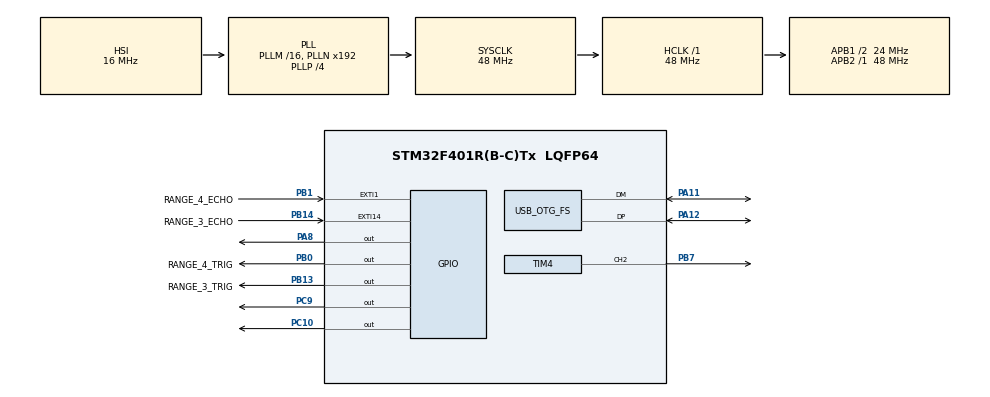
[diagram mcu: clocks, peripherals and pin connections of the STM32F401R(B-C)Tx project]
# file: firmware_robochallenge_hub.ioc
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Dma.Request0=TIM4_CH2
Dma.TIM4_CH2.0.Direction=DMA_MEMORY_TO_PERIPH
Dma.TIM4_CH2.0.FIFOMode=DMA_FIFOMODE_DISABLE
Dma.TIM4_CH2.0.Instance=DMA1_Stream3
Dma.TIM4_CH2.0.MemDataAlignment=DMA_MDATAALIGN_HALFWORD
Dma.TIM4_CH2.0.MemInc=DMA_MINC_ENABLE
Dma.TIM4_CH2.0.Mode=DMA_NORMAL
Dma.TIM4_CH2.0.PeriphDataAlignment=DMA_PDATAALIGN_HALFWORD
Dma.TIM4_CH2.0.PeriphInc=DMA_PINC_DISABLE
Dma.TIM4_CH2.0.Priority=DMA_PRIORITY_VERY_HIGH
FREERTOS.Tasks01=test_task,24,128,test_task_fun,Default,NULL,Dynamic,NULL,NULL;DistanceSensorT,8,128,DistanceSensorTask_Init,Default,NULL,Dynamic,NULL,NULL;streaming_task,8,128,streaming_task_entry,Default,NULL,Dynamic,NULL,NULL
FREERTOS.configUSE_NEWLIB_REENTRANT=1
Mcu.Family=STM32F4
Mcu.Name=STM32F401R(B-C)Tx
Mcu.Package=LQFP64
NVIC.DMA1_Stream3_IRQn=true\:2\:0\:true\:false\:true\:false\:false\:true\:true
NVIC.EXTI15_10_IRQn=true\:5\:0\:false\:false\:true\:true\:true\:true\:true
NVIC.EXTI1_IRQn=true\:5\:0\:false\:false\:true\:true\:true\:true\:true
NVIC.OTG_FS_IRQn=true\:5\:0\:false\:false\:true\:true\:false\:true\:true
NVIC.PriorityGroup=NVIC_PRIORITYGROUP_4
NVIC.TIM1_TRG_COM_TIM11_IRQn=true\:15\:0\:false\:false\:true\:false\:false\:true\:true
NVIC.TIM3_IRQn=true\:5\:0\:false\:false\:true\:true\:true\:true\:true
NVIC.TimeBase=TIM1_TRG_COM_TIM11_IRQn
NVIC.TimeBaseIP=TIM11
PA11.Mode=Device_Only
PA11.Signal=USB_OTG_FS_DM
PA12.Mode=Device_Only
PA12.Signal=USB_OTG_FS_DP
PA13.Mode=Serial_Wire
PA13.Signal=SYS_JTMS-SWDIO
PA14.Mode=Serial_Wire
PA14.Signal=SYS_JTCK-SWCLK
PA8.Signal=GPIO_Output
PB0.GPIO_Label=RANGE_4_TRIG
PB0.GPIO_Speed=GPIO_SPEED_FREQ_MEDIUM
PB0.Signal=GPIO_Output
PB1.GPIO_Label=RANGE_4_ECHO
PB1.GPIO_ModeDefaultEXTI=GPIO_MODE_IT_RISING_FALLING
PB1.GPIO_PuPd=GPIO_PULLDOWN
PB1.Signal=GPXTI1
PB13.GPIO_Label=RANGE_3_TRIG
PB13.GPIO_Speed=GPIO_SPEED_FREQ_MEDIUM
PB13.Signal=GPIO_Output
PB14.GPIO_Label=RANGE_3_ECHO
PB14.GPIO_ModeDefaultEXTI=GPIO_MODE_IT_RISING_FALLING
PB14.GPIO_PuPd=GPIO_PULLDOWN
PB14.Signal=GPXTI14
PB7.Signal=S_TIM4_CH2
PC10.Signal=GPIO_Output
PC9.Signal=GPIO_Output
ProjectManager.HeapSize=0x200
ProjectManager.StackSize=0x400
ProjectManager.TargetToolchain=STM32CubeIDE
RCC.AHBFreq_Value=48000000
RCC.APB1CLKDivider=RCC_HCLK_DIV2
RCC.APB1Freq_Value=24000000
RCC.APB1TimFreq_Value=48000000
RCC.APB2Freq_Value=48000000
RCC.APB2TimFreq_Value=48000000
RCC.CortexFreq_Value=48000000
RCC.HCLKFreq_Value=48000000
RCC.HSE_VALUE=25000000
RCC.HSI_VALUE=16000000
RCC.LSE_VALUE=32768
RCC.PLLP=RCC_PLLP_DIV4
RCC.PLLSource=RCC_PLLSOURCE_HSI
RCC.SYSCLKFreq_VALUE=48000000
RCC.SYSCLKSource=RCC_SYSCLKSOURCE_PLLCLK
RCC.VCOOutputFreq_Value=192000000
SH.S_TIM4_CH2.0=TIM4_CH2,PWM Generation2 CH2
TIM3.CounterMode=TIM_COUNTERMODE_DOWN
TIM3.Prescaler=240
TIM4.Channel-PWM\ Generation2\ CH2=TIM_CHANNEL_2
TIM4.Period=60-1
USB_DEVICE.CLASS_NAME_FS=CDC
USB_DEVICE.VirtualMode=Cdc
USB_DEVICE.VirtualModeFS=Cdc_FS
USB_OTG_FS.VirtualMode=Device_Only
VP_FREERTOS_VS_CMSIS_V2.Mode=CMSIS_V2
VP_SYS_VS_tim11.Mode=TIM11
VP_TIM3_VS_ClockSourceINT.Mode=Internal
VP_TIM4_VS_ClockSourceINT.Mode=Internal
VP_USB_DEVICE_VS_USB_DEVICE_CDC_FS.Mode=CDC_FS
board=custom

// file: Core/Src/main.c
/* USER CODE BEGIN Header */
/**
 ******************************************************************************
 * @file           : main.c
 * @brief          : Main program body
 ******************************************************************************
 * @attention
 *
 * Copyright (c) 2022 STMicroelectronics.
 * All rights reserved.
 *
 * This software is licensed under terms that can be found in the LICENSE file
 * in the root directory of this software component.
 * If no LICENSE file comes with this software, it is provided AS-IS.
 *
 ******************************************************************************
 */
/* USER CODE END Header */
#include "main.h"
#include "cmsis_os.h"
#include "usb_device.h"

/* USER CODE BEGIN Includes */
#include "firmware.h"

/* USER CODE END Includes */

 TIM_HandleTypeDef htim3;
TIM_HandleTypeDef htim4;
DMA_HandleTypeDef hdma_tim4_ch2;

/* Definitions for test_task */
osThreadId_t test_taskHandle;
const osThreadAttr_t test_task_attributes = {
  .name = "test_task",
  .stack_size = 128 * 4,
  .priority = (osPriority_t) osPriorityNormal,
};
/* Definitions for DistanceSensorT */
osThreadId_t DistanceSensorTHandle;
const osThreadAttr_t DistanceSensorT_attributes = {
  .name = "DistanceSensorT",
  .stack_size = 128 * 4,
  .priority = (osPriority_t) osPriorityLow,
};
/* Definitions for streaming_task */
osThreadId_t streaming_taskHandle;
const osThreadAttr_t streaming_task_attributes = {
  .name = "streaming_task",
  .stack_size = 128 * 4,
  .priority = (osPriority_t) osPriorityLow,
};

void SystemClock_Config(void);
static void MX_GPIO_Init(void);
static void MX_DMA_Init(void);
static void MX_TIM4_Init(void);
static void MX_TIM3_Init(void);
void test_task_fun(void *argument);
void DistanceSensorTask_Init(void *argument);
void streaming_task_entry(void *argument);

int main(void)
{

  /* MCU Configuration--------------------------------------------------------*/

  /* Reset of all peripherals, Initializes the Flash interface and the Systick. */
  HAL_Init();

  /* Configure the system clock */
  SystemClock_Config();

  /* Initialize all configured peripherals */
  MX_GPIO_Init();
  MX_DMA_Init();
  MX_TIM4_Init();
  MX_TIM3_Init();
  /* USER CODE BEGIN 2 */
	//Timer used for distance Sensors
	distance_sensor_timer = &htim3;

	ws2812_init(&htim4);

	firmware_init();
  /* USER CODE END 2 */

  /* Init scheduler */
  osKernelInitialize();

  /* Create the thread(s) */
  /* creation of test_task */
  test_taskHandle = osThreadNew(test_task_fun, NULL, &test_task_attributes);

  /* creation of DistanceSensorT */
  DistanceSensorTHandle = osThreadNew(DistanceSensorTask_Init, NULL, &DistanceSensorT_attributes);

  /* creation of streaming_task */
  streaming_taskHandle = osThreadNew(streaming_task_entry, NULL, &streaming_task_attributes);

  /* Start scheduler */
  osKernelStart();

  /* We should never get here as control is now taken by the scheduler */
  /* Infinite loop */
	while (1) {

	}
}

void SystemClock_Config(void)
{
  RCC_OscInitTypeDef RCC_OscInitStruct = {0};
  RCC_ClkInitTypeDef RCC_ClkInitStruct = {0};

  /** Configure the main internal regulator output voltage
  */
  __HAL_RCC_PWR_CLK_ENABLE();
  __HAL_PWR_VOLTAGESCALING_CONFIG(PWR_REGULATOR_VOLTAGE_SCALE2);

  /** Initializes the RCC Oscillators according to the specified parameters
  * in the RCC_OscInitTypeDef structure.
  */
  RCC_OscInitStruct.OscillatorType = RCC_OSCILLATORTYPE_HSI;
  RCC_OscInitStruct.HSIState = RCC_HSI_ON;
  RCC_OscInitStruct.HSICalibrationValue = RCC_HSICALIBRATION_DEFAULT;
  RCC_OscInitStruct.PLL.PLLState = RCC_PLL_ON;
  RCC_OscInitStruct.PLL.PLLSource = RCC_PLLSOURCE_HSI;
  RCC_OscInitStruct.PLL.PLLM = 16;
  RCC_OscInitStruct.PLL.PLLN = 192;
  RCC_OscInitStruct.PLL.PLLP = RCC_PLLP_DIV4;
  RCC_OscInitStruct.PLL.PLLQ = 4;
  if (HAL_RCC_OscConfig(&RCC_OscInitStruct) != HAL_OK)
  {
    Error_Handler();
  }

  /** Initializes the CPU, AHB and APB buses clocks
  */
  RCC_ClkInitStruct.ClockType = RCC_CLOCKTYPE_HCLK|RCC_CLOCKTYPE_SYSCLK
                              |RCC_CLOCKTYPE_PCLK1|RCC_CLOCKTYPE_PCLK2;
  RCC_ClkInitStruct.SYSCLKSource = RCC_SYSCLKSOURCE_PLLCLK;
  RCC_ClkInitStruct.AHBCLKDivider = RCC_SYSCLK_DIV1;
  RCC_ClkInitStruct.APB1CLKDivider = RCC_HCLK_DIV2;
  RCC_ClkInitStruct.APB2CLKDivider = RCC_HCLK_DIV1;

  if (HAL_RCC_ClockConfig(&RCC_ClkInitStruct, FLASH_LATENCY_1) != HAL_OK)
  {
    Error_Handler();
  }
}

static void MX_TIM3_Init(void)
{

  TIM_ClockConfigTypeDef sClockSourceConfig = {0};
  TIM_MasterConfigTypeDef sMasterConfig = {0};

  htim3.Instance = TIM3;
  htim3.Init.Prescaler = 240;
  htim3.Init.CounterMode = TIM_COUNTERMODE_DOWN;
  htim3.Init.Period = 65535;
  htim3.Init.ClockDivision = TIM_CLOCKDIVISION_DIV1;
  htim3.Init.AutoReloadPreload = TIM_AUTORELOAD_PRELOAD_DISABLE;
  if (HAL_TIM_Base_Init(&htim3) != HAL_OK)
  {
    Error_Handler();
  }
  sClockSourceConfig.ClockSource = TIM_CLOCKSOURCE_INTERNAL;
  if (HAL_TIM_ConfigClockSource(&htim3, &sClockSourceConfig) != HAL_OK)
  {
    Error_Handler();
  }
  sMasterConfig.MasterOutputTrigger = TIM_TRGO_RESET;
  sMasterConfig.MasterSlaveMode = TIM_MASTERSLAVEMODE_DISABLE;
  if (HAL_TIMEx_MasterConfigSynchronization(&htim3, &sMasterConfig) != HAL_OK)
  {
    Error_Handler();
  }

}

static void MX_TIM4_Init(void)
{

  TIM_ClockConfigTypeDef sClockSourceConfig = {0};
  TIM_MasterConfigTypeDef sMasterConfig = {0};
  TIM_OC_InitTypeDef sConfigOC = {0};

  htim4.Instance = TIM4;
  htim4.Init.Prescaler = 0;
  htim4.Init.CounterMode = TIM_COUNTERMODE_UP;
  htim4.Init.Period = 60-1;
  htim4.Init.ClockDivision = TIM_CLOCKDIVISION_DIV1;
  htim4.Init.AutoReloadPreload = TIM_AUTORELOAD_PRELOAD_DISABLE;
  if (HAL_TIM_Base_Init(&htim4) != HAL_OK)
  {
    Error_Handler();
  }
  sClockSourceConfig.ClockSource = TIM_CLOCKSOURCE_INTERNAL;
  if (HAL_TIM_ConfigClockSource(&htim4, &sClockSourceConfig) != HAL_OK)
  {
    Error_Handler();
  }
  if (HAL_TIM_PWM_Init(&htim4) != HAL_OK)
  {
    Error_Handler();
  }
  sMasterConfig.MasterOutputTrigger = TIM_TRGO_RESET;
  sMasterConfig.MasterSlaveMode = TIM_MASTERSLAVEMODE_DISABLE;
  if (HAL_TIMEx_MasterConfigSynchronization(&htim4, &sMasterConfig) != HAL_OK)
  {
    Error_Handler();
  }
  sConfigOC.OCMode = TIM_OCMODE_PWM1;
  sConfigOC.Pulse = 0;
  sConfigOC.OCPolarity = TIM_OCPOLARITY_HIGH;
  sConfigOC.OCFastMode = TIM_OCFAST_DISABLE;
  if (HAL_TIM_PWM_ConfigChannel(&htim4, &sConfigOC, TIM_CHANNEL_2) != HAL_OK)
  {
    Error_Handler();
  }
  HAL_TIM_MspPostInit(&htim4);

}

static void MX_DMA_Init(void)
{

  /* DMA controller clock enable */
  __HAL_RCC_DMA1_CLK_ENABLE();

  /* DMA interrupt init */
  /* DMA1_Stream3_IRQn interrupt configuration */
  HAL_NVIC_SetPriority(DMA1_Stream3_IRQn, 2, 0);
  HAL_NVIC_EnableIRQ(DMA1_Stream3_IRQn);

}

static void MX_GPIO_Init(void)
{
  GPIO_InitTypeDef GPIO_InitStruct = {0};

  /* GPIO Ports Clock Enable */
  __HAL_RCC_GPIOB_CLK_ENABLE();
  __HAL_RCC_GPIOC_CLK_ENABLE();
  __HAL_RCC_GPIOA_CLK_ENABLE();

  /*Configure GPIO pin Output Level */
  HAL_GPIO_WritePin(GPIOB, RANGE_4_TRIG_Pin|RANGE_3_TRIG_Pin, GPIO_PIN_RESET);

  /*Configure GPIO pin Output Level */
  HAL_GPIO_WritePin(GPIOC, GPIO_PIN_9|GPIO_PIN_10, GPIO_PIN_RESET);

  /*Configure GPIO pin Output Level */
  HAL_GPIO_WritePin(GPIOA, GPIO_PIN_8, GPIO_PIN_RESET);

  /*Configure GPIO pins : RANGE_4_TRIG_Pin RANGE_3_TRIG_Pin */
  GPIO_InitStruct.Pin = RANGE_4_TRIG_Pin|RANGE_3_TRIG_Pin;
  GPIO_InitStruct.Mode = GPIO_MODE_OUTPUT_PP;
  GPIO_InitStruct.Pull = GPIO_NOPULL;
  GPIO_InitStruct.Speed = GPIO_SPEED_FREQ_MEDIUM;
  HAL_GPIO_Init(GPIOB, &GPIO_InitStruct);

  /*Configure GPIO pins : RANGE_4_ECHO_Pin RANGE_3_ECHO_Pin */
  GPIO_InitStruct.Pin = RANGE_4_ECHO_Pin|RANGE_3_ECHO_Pin;
  GPIO_InitStruct.Mode = GPIO_MODE_IT_RISING_FALLING;
  GPIO_InitStruct.Pull = GPIO_PULLDOWN;
  HAL_GPIO_Init(GPIOB, &GPIO_InitStruct);

  /*Configure GPIO pins : PC9 PC10 */
  GPIO_InitStruct.Pin = GPIO_PIN_9|GPIO_PIN_10;
  GPIO_InitStruct.Mode = GPIO_MODE_OUTPUT_PP;
  GPIO_InitStruct.Pull = GPIO_NOPULL;
  GPIO_InitStruct.Speed = GPIO_SPEED_FREQ_LOW;
  HAL_GPIO_Init(GPIOC, &GPIO_InitStruct);

  /*Configure GPIO pin : PA8 */
  GPIO_InitStruct.Pin = GPIO_PIN_8;
  GPIO_InitStruct.Mode = GPIO_MODE_OUTPUT_PP;
  GPIO_InitStruct.Pull = GPIO_NOPULL;
  GPIO_InitStruct.Speed = GPIO_SPEED_FREQ_LOW;
  HAL_GPIO_Init(GPIOA, &GPIO_InitStruct);

  /* EXTI interrupt init*/
  HAL_NVIC_SetPriority(EXTI1_IRQn, 5, 0);
  HAL_NVIC_EnableIRQ(EXTI1_IRQn);

  HAL_NVIC_SetPriority(EXTI15_10_IRQn, 5, 0);
  HAL_NVIC_EnableIRQ(EXTI15_10_IRQn);

}

void test_task_fun(void *argument)
{
  /* init code for USB_DEVICE */
  MX_USB_DEVICE_Init();
  /* USER CODE BEGIN 5 */
	/* Infinite loop */
	for (;;) {
		osDelay(250);
	}
  /* USER CODE END 5 */
}

void DistanceSensorTask_Init(void *argument)
{
  /* USER CODE BEGIN DistanceSensorTask_Init */
	distance_meas_task(&distance_sensor_handler);
  /* USER CODE END DistanceSensorTask_Init */
}

void streaming_task_entry(void *argument)
{
  /* USER CODE BEGIN streaming_task_entry */
  /* Infinite loop */
  for(;;)
  {

	  // Send all distance sensors
	  for (int i=0;i<distance_sensor_handler.num_sensors; i++){
		  msg_stream_distance(msg_out_buf, distance_sensor_handler.distance_sensors[i]);
	  }
    osDelay(100);
  }
  /* USER CODE END streaming_task_entry */
}

void HAL_TIM_PeriodElapsedCallback(TIM_HandleTypeDef *htim)
{
  if (htim->Instance == TIM11) {
    HAL_IncTick();
  }
  /* USER CODE BEGIN Callback 1 */
	if (htim->Instance == TIM3) {
		distance_sensor_timer_callback();
	}
  /* USER CODE END Callback 1 */
}

void Error_Handler(void)
{
	__disable_irq();
	while (1) {
	}
}
